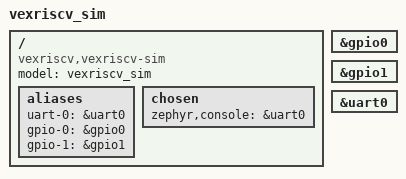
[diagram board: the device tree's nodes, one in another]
/*
 * Copyright (c) 2019 Phytec Messtechnik GmbH
 *
 * SPDX-License-Identifier: Apache-2.0
 */

/dts-v1/;

#include <vexriscv.dtsi>

/ {
	model = "vexriscv_sim";
	compatible = "vexriscv,vexriscv-sim";

	aliases {
		uart-0 = &uart0;
		gpio-0 = &gpio0;
		gpio-1 = &gpio1;
	};

	chosen {
		zephyr,console = &uart0;
	};
/*
	leds {
		compatible = "gpio-leds";
		green_led_0: led_0 {
			gpios = <&gpio1 0 0>;
			label = "Green LED";
		};
		yellow_led_1: led_1 {
			gpios = <&gpio1 1 0>;
			label = "Yellow LED";
		};
		red_led_2: led_2 {
			gpios = <&gpio1 2 0>;
			label = "Red LED";
		};
		heartbeat_led_3: led_3 {
			gpios = <&gpio1 3 0>;
			label = "Heartbeat LED";
		};
	};
*/
};

&gpio0 {
	status = "ok";
};

&gpio1 {
	status = "ok";
};

&uart0 {
	status = "ok";
};
